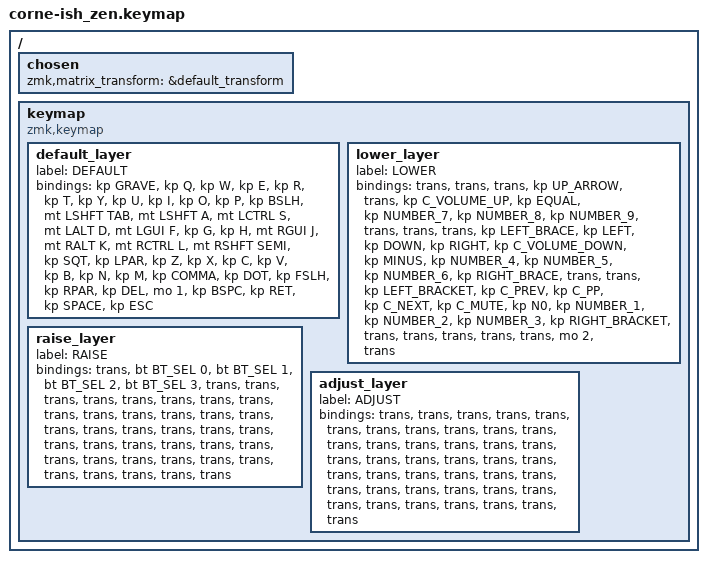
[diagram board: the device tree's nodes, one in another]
/*
*
* Copyright (c) 2021 Darryl deHaan
* SPDX-License-Identifier: MIT
*
*/

#include <behaviors.dtsi>
#include <dt-bindings/zmk/bt.h>
#include <dt-bindings/zmk/keys.h>

/ {
    chosen {
        zmk,matrix_transform = &default_transform;

        //zmk,matrix_transform = &five_column_transform;
    };
};

/*
 * Translated from VIA/QMK Reverb to ZMK Corne-ish Zen
 */

/ {
    keymap {
        compatible = "zmk,keymap";

        default_layer {
            label = "DEFAULT";

            // -----------------------------------------------------------------------------------------
            // |  GRAVE |  Q  |  W  |  E  |  R  |  T  |   |  Y  |  U   |  I  |  O  |  P  | BSLH |
            // | TAB/SFT| A/S | S/C | D/A | F/G |  G  |   |  H  | J/G  | K/A | L/C | ;/S |  '   |
            // |    (   |  Z  |  X  |  C  |  V  |  B  |   |  N  |  M   |  ,  |  .  |  /  |  )   |
            //                       | DEL | LWR | BSPC|   | RET | SPC  | ESC |

            bindings = <
&kp GRAVE  &kp Q  &kp W  &kp E  &kp R  &kp T  &kp Y  &kp U  &kp I  &kp O  &kp P  &kp BSLH  &mt LSHFT TAB  &mt LSHFT A  &mt LCTRL S  &mt LALT D  &mt LGUI F  &kp G  &kp H  &mt RGUI J  &mt RALT K  &mt RCTRL L  &mt RSHFT SEMI  &kp SQT  &kp LPAR  &kp Z  &kp X  &kp C  &kp V  &kp B  &kp N  &kp M  &kp COMMA  &kp DOT  &kp FSLH  &kp RPAR  &kp DEL  &mo 1  &kp BSPC  &kp RET  &kp SPACE  &kp ESC
            >;
        };

        lower_layer {
            label = "LOWER";

            // -----------------------------------------------------------------------------------------
            // | TRANS |TRANS|TRANS| UP  |TRANS| VOLU|   |  =  |  7   |  8  |  9  |TRANS| TRANS |
            // | TRANS |  {  | LEFT| DOWN| RGHT| VOLD|   |  -  |  4   |  5  |  6  |  }  | TRANS |
            // | TRANS |  [  | PRV | PLAY| NEXT| MUTE|   |  0  |  1   |  2  |  3  |  ]  | TRANS |
            //                       |TRANS|TRANS|TRANS|  |TRANS| ADJ  |TRANS|

            bindings = <
&trans  &trans  &trans  &kp UP_ARROW  &trans  &kp C_VOLUME_UP  &kp EQUAL  &kp NUMBER_7  &kp NUMBER_8  &kp NUMBER_9  &trans  &trans  &trans  &kp LEFT_BRACE  &kp LEFT  &kp DOWN  &kp RIGHT  &kp C_VOLUME_DOWN  &kp MINUS  &kp NUMBER_4  &kp NUMBER_5  &kp NUMBER_6  &kp RIGHT_BRACE  &trans  &trans  &kp LEFT_BRACKET  &kp C_PREV  &kp C_PP  &kp C_NEXT  &kp C_MUTE  &kp N0  &kp NUMBER_1  &kp NUMBER_2  &kp NUMBER_3  &kp RIGHT_BRACKET  &trans  &trans  &trans  &trans  &trans  &mo 2  &trans
            >;
        };

        raise_layer {
            label = "RAISE";
            bindings = <
&trans  &bt BT_SEL 0  &bt BT_SEL 1  &bt BT_SEL 2  &bt BT_SEL 3  &trans  &trans  &trans  &trans  &trans  &trans  &trans  &trans  &trans  &trans  &trans  &trans  &trans  &trans  &trans  &trans  &trans  &trans  &trans  &trans  &trans  &trans  &trans  &trans  &trans  &trans  &trans  &trans  &trans  &trans  &trans  &trans  &trans  &trans  &trans  &trans  &trans
            >;
        };

        adjust_layer {
            label = "ADJUST";
            bindings = <
&trans  &trans  &trans  &trans  &trans  &trans  &trans  &trans  &trans  &trans  &trans  &trans  &trans  &trans  &trans  &trans  &trans  &trans  &trans  &trans  &trans  &trans  &trans  &trans  &trans  &trans  &trans  &trans  &trans  &trans  &trans  &trans  &trans  &trans  &trans  &trans  &trans  &trans  &trans  &trans  &trans  &trans
            >;
        };
    };
};
